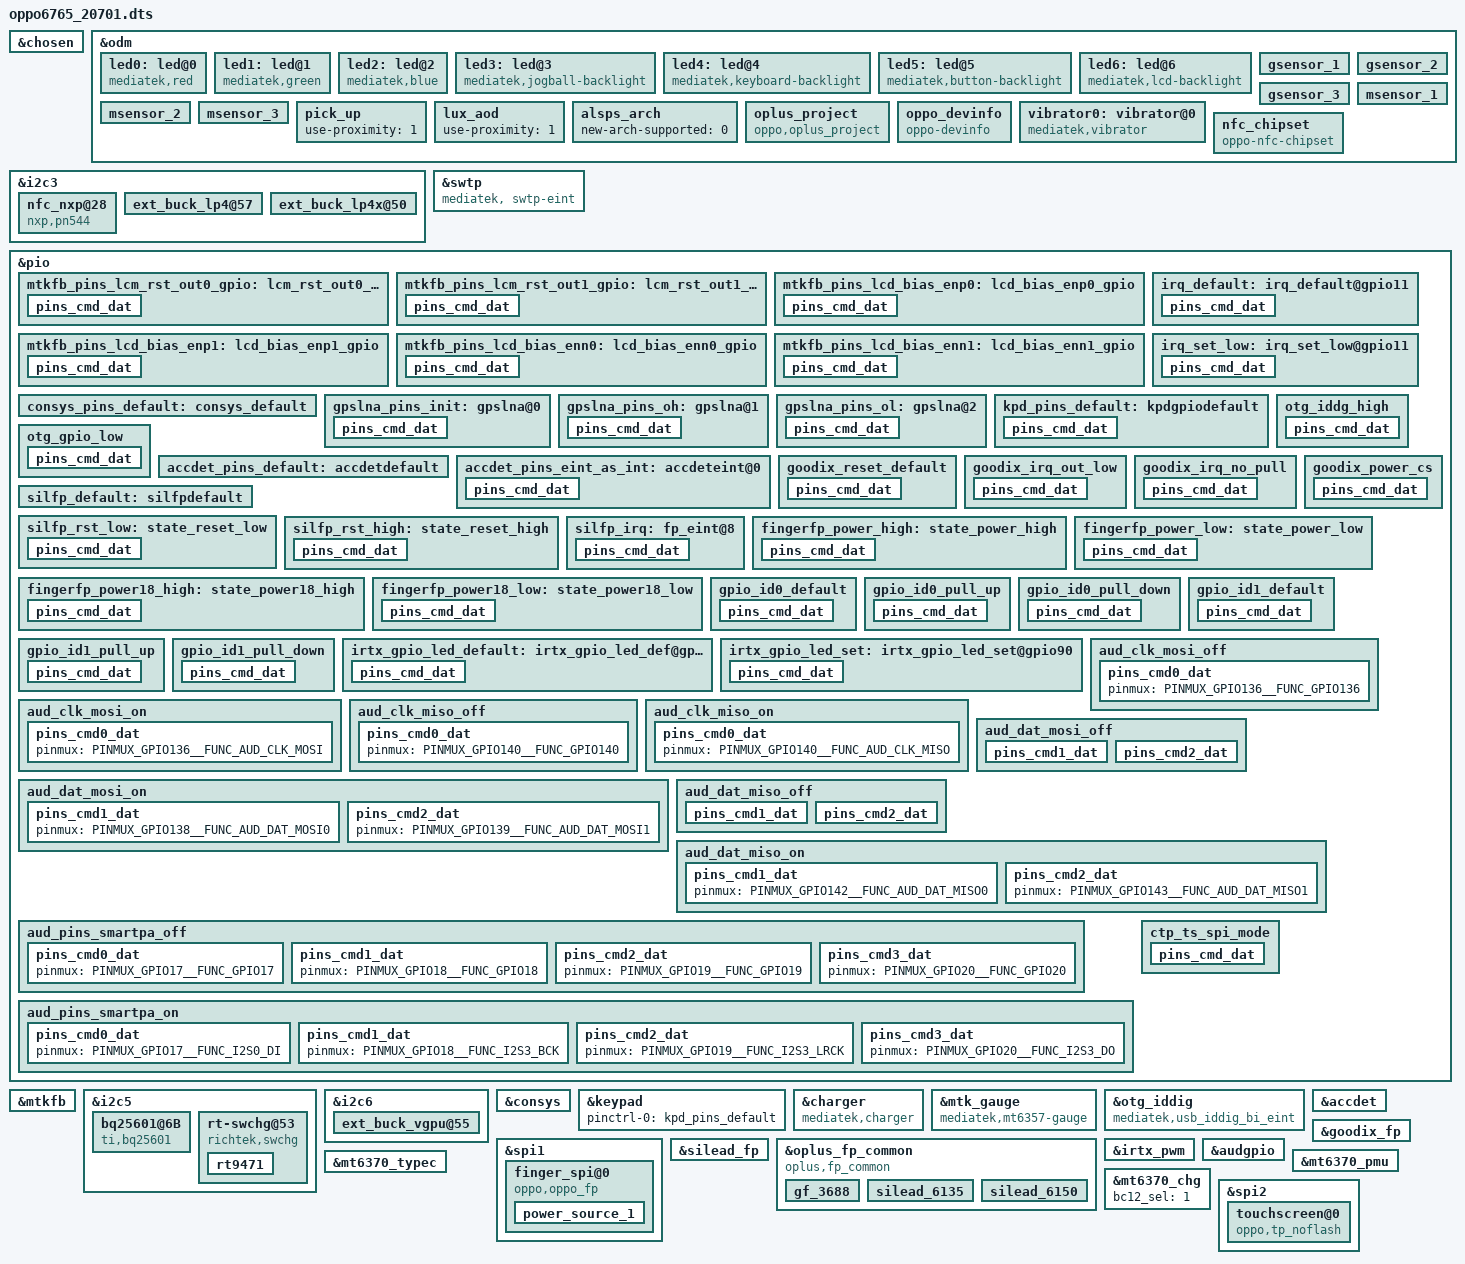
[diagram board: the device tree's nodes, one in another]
// SPDX-License-Identifier: GPL-2.0+
/*
 * Copyright (c) 2019 MediaTek Inc.
 *
 */

#include <dt-bindings/interrupt-controller/arm-gic.h>
#include <dt-bindings/interrupt-controller/irq.h>
#include <dt-bindings/pinctrl/mt6765-pinfunc.h>
#include <dt-bindings/clock/mt6765-clk.h>

/dts-v1/;
/plugin/;

/* chosen */
&chosen {

	/* fpga may has no lk, we need to specify display info here */
	/* fb buffer is reserved using this dts by memory node above */
	atag,videolfb-fb_base_h = <0x0>;
	atag,videolfb-fb_base_l = <0x5e605000>;
	atag,videolfb-islcmfound = <1>;
	/* because no lk, so lcm is not inited */
	atag,videolfb-islcm_inited = <0>;
	atag,videolfb-fps= <6000>;
	atag,videolfb-vramSize= <0x017bb000>;
	atag,videolfb-lcmname= "nt35695B_fhd_dsi_cmd_auo_rt5081_drv";
};

&odm {
	led0:led@0 {
		compatible = "mediatek,red";
		led_mode = <0>;
		data = <1>;
		pwm_config = <0 0 0 0 0>;
	};
	led1:led@1 {
		compatible = "mediatek,green";
		led_mode = <0>;
		data = <1>;
		pwm_config = <0 0 0 0 0>;
	};
	led2:led@2 {
		compatible = "mediatek,blue";
		led_mode = <0>;
		data = <1>;
		pwm_config = <0 0 0 0 0>;
	};
	led3:led@3 {
		compatible = "mediatek,jogball-backlight";
		led_mode = <0>;
		data = <1>;
		pwm_config = <0 0 0 0 0>;
	};
	led4:led@4 {
		compatible = "mediatek,keyboard-backlight";
		led_mode = <0>;
		data = <1>;
		pwm_config = <0 0 0 0 0>;
	};
	led5:led@5 {
		compatible = "mediatek,button-backlight";
		led_mode = <0>;
		data = <1>;
		pwm_config = <0 0 0 0 0>;
	};
	led6:led@6 {
		compatible = "mediatek,lcd-backlight";
		//#ifndef ODM_HQ_EDIT
		led_mode = <4>;
		//#endif
		data = <1>;
		pwm_config = <0 3 0 0 0>;
	};
/*sensor start */
	/*
	enum {
		LIS3DH,
		LSM6DS3,
		BMI160,
		LIS2HH12,
		LSM6DSM,
		BMI2XY,
		LSM6DSO,
		BMA2X2,
		KX022,
		SC7A20,
		MC34X9,
		STK832X,
	};
	*/
	gsensor_1: gsensor_1 {
		status = "okay";
		sensor_name = <7>;//BMA2X2
		i2c_num = <0>;
		i2c_addr = <18>;
		direction = <3>;
		eint_num = <12>;
		step_count_7_en = <1>;
		config_miso = <1>;
		correct_y_bias = <1>;
	};
	gsensor_2: gsensor_2 {
		status = "okay";
		sensor_name = <10>;//MC34X9
		i2c_num = <0>;
		i2c_addr = <0x18>;
		direction = <3>;
		eint_num = <12>;
		step_count_7_en = <1>;
		config_miso = <1>;
		correct_y_bias = <1>;
	};
	gsensor_3: gsensor_3 {
		status = "okay";
		sensor_name = <11>;//STK832X
		i2c_num = <0>;
		i2c_addr = <0x18>;
		direction = <3>;
		eint_num = <12>;
		step_count_7_en = <1>;
		config_miso = <1>;
		correct_y_bias = <1>;
	};
	/*
	enum {
		AKM09911,
		MMC3530,
		MMC5603,
		MXG4300,
		AF6133,
		AF6133E,
	};
	*/
	msensor_1: msensor_1 {
		status = "okay";
		sensor_name = <0>;//AKM09918
		i2c_num = <0>;
		i2c_addr = <0x0c>;
		direction = <3>;
		eint_num = <0>;
	};

	msensor_2: msensor_2 {
		status = "okay";
		sensor_name = <2>;//MMC5603
		i2c_num = <0>;
		i2c_addr = <0x30>;
		direction = <3>;
		eint_num = <0>;
	};
	
	msensor_3: msensor_3 {
		status = "okay";
		sensor_name = <5>;//AF6133E
		i2c_num = <0>;
		i2c_addr = <0x0c>;
		direction = <4>;
		eint_num = <0>;
	};
	pick_up: pick_up {
		status = "okay";
		use-proximity = <1>;
	};
	lux_aod: lux_aod {
		status = "okay";
		use-proximity = <1>;
	};
	alsps_arch: alsps_arch {
		status = "okay";
		new-arch-supported = <0>;
	};
/*sensor end */
/*VNDOR_EDIT oppo project start */
	oplus_project:oplus_project {
		compatible = "oppo,oplus_project";
	};
	oppo_devinfo:oppo_devinfo {
		compatible = "oppo-devinfo";
	};
	vibrator0:vibrator@0 {
		compatible = "mediatek,vibrator";
		vib_timer = <25>;
		vib_limit = <9>;
		vib_vol= <9>;
	};

//#ifdef OPLUS_FEATURE_NFC_CONSOFT
    nfc_chipset:nfc_chipset {
        compatible = "oppo-nfc-chipset";
        chipset-20701-182 = "PN557";
        chipset-20701-183 = "PN557";
    };
//#endif /* OPLUS_FEATURE_NFC_CONSOFT */
};

//#ifdef OPLUS_FEATURE_NFC_BRINGUP
&i2c3 {
       status = "okay";
       nfc_nxp@28 {
               compatible = "nxp,pn544";
               reg = <0x28>;
               nxp,pn544-irq = <&pio 4 0x0>;
               nxp,pn544-ven = <&pio 159 0x0>;
               nxp,pn544-fw-dwnld = <&pio 8 0x0>;
               //pn544-clkreq = <&pio 89 0x0>;
               interrupt-parent = <&pio>;
       };
};
//#endif /* OPLUS_FEATURE_NFC_BRINGUP */

//#ifdef OPLUS_BUG_COMPATIBILITY
&swtp {
		compatible = "mediatek, swtp-eint";
	};
//#endif /*OPLUS_BUG_COMPATIBILITY*/

/* DISPSYS GPIO standardization */
&pio {
	mtkfb_pins_lcm_rst_out0_gpio: lcm_rst_out0_gpio {
		pins_cmd_dat {
			pinmux = <PINMUX_GPIO45__FUNC_GPIO45>;
			slew-rate = <1>;
			output-low;
		};
	};

	mtkfb_pins_lcm_rst_out1_gpio: lcm_rst_out1_gpio {
		pins_cmd_dat {
			pinmux = <PINMUX_GPIO45__FUNC_GPIO45>;
			slew-rate = <1>;
			output-high;
		};
	};

	mtkfb_pins_lcd_bias_enp0: lcd_bias_enp0_gpio {
		pins_cmd_dat {
			pinmux = <PINMUX_GPIO166__FUNC_GPIO166>;
			slew-rate = <1>;
			output-low;
		};
	};

	mtkfb_pins_lcd_bias_enp1: lcd_bias_enp1_gpio {
		pins_cmd_dat {
			pinmux = <PINMUX_GPIO166__FUNC_GPIO166>;
			slew-rate = <1>;
			output-high;
		};
	};

	mtkfb_pins_lcd_bias_enn0: lcd_bias_enn0_gpio {
		pins_cmd_dat {
			pinmux = <PINMUX_GPIO165__FUNC_GPIO165>;
			slew-rate = <1>;
			output-low;
		};
	};

	mtkfb_pins_lcd_bias_enn1: lcd_bias_enn1_gpio {
		pins_cmd_dat {
			pinmux = <PINMUX_GPIO165__FUNC_GPIO165>;
			slew-rate = <1>;
			output-high;
		};
	};
};

&mtkfb {
	pinctrl-names = "lcm_rst_out0_gpio", "lcm_rst_out1_gpio",
		"lcd_bias_enp0_gpio", "lcd_bias_enp1_gpio",
		 "lcd_bias_enn0_gpio", "lcd_bias_enn1_gpio";
	pinctrl-0 = <&mtkfb_pins_lcm_rst_out0_gpio>;
	pinctrl-1 = <&mtkfb_pins_lcm_rst_out1_gpio>;
	pinctrl-2 = <&mtkfb_pins_lcd_bias_enp0>;
	pinctrl-3 = <&mtkfb_pins_lcd_bias_enp1>;
	pinctrl-4 = <&mtkfb_pins_lcd_bias_enn0>;
	pinctrl-5 = <&mtkfb_pins_lcd_bias_enn1>;
	status = "okay";
};

/* DISPSYS GPIO standardization end */

&i2c3 {
	ext_buck_lp4@57 {
		regulator-name ="ext_buck_vdd2";
		regulator-min-microvolt = <300000>;
		regulator-max-microvolt = <1300000>;
		vsel_pin = <0>;
	};

	ext_buck_lp4x@50 {
		regulator-name ="ext_buck_vddq";
		regulator-min-microvolt = <300000>;
		regulator-max-microvolt = <1300000>;
		vsel_pin = <1>;
	};
};

&i2c5 {
	bq25601@6B {
		compatible = "ti,bq25601";
		reg = <0x6b>;
		interrupt-parent = <&pio>;
		interrupts = <11 IRQ_TYPE_EDGE_FALLING 11 0>;
		ti,bq2560x,usb-vlim = <4600>;
		ti,bq2560x,usb-ilim = <500>;
		ti,bq2560x,usb-vreg = <4400>;
		ti,bq2560x,usb-ichg = <500>;
		ti,bq2560x,precharge-current = <256>;
		ti,bq2560x,termination-current = <240>;
		ti,bq2560x,boost-voltage = <4998>;
		ti,bq2560x,boost-current = <1200>;
		ti,bq2560x,enable_term;
		ti,bq2560x,stat-pin-ctrl = <3>;
		ti,bq2560x,vac-ovp-threshold = <6500>;
		ti,bq2560x,charge-detect-enable;

		charger_name = "primary_chg";
		eint_name = "bq2560x";

		pinctrl-names = "irq_default", "irq_set_low";
		pinctrl-0 = <&irq_default>;
		pinctrl-1 = <&irq_set_low>;

		status = "okay";
	};

	rt-swchg@53 {
		compatible = "richtek,swchg";
		reg = <0x53>;
		status = "okay";

		rt,intr_gpio_num = <11>; /* direct defined GPIO num */
		rt,intr_gpio = <&pio 11 0x0>; /* GPIO */
		rt9471 {
			/*
			 * Charger name
			 * Main charger: primary_chg
			 * Slave charger: secondary_chg
			 */
			charger_name = "primary_chg";
			chg_alias_name = "rt9471_chg";
			rm-slave-addr = /bits/ 8 <0x53>;
			rm-name = "rt9471";
			interrupt-names = "wdt", "chg_mivr", "vbus_gd",
					  "bc12_done", "detach", "vac_ov",
					  "otg_fault", "chg_rdy", "chg_done";
			ichg = <1000000>;		/* uA */
			aicr = <500000>;		/* uA */
			mivr = <4400000>;		/* uV */
			cv = <4350000>;			/* uV */
			ieoc = <200000>;		/* uA */
			safe-tmr = <10>;		/* hour */
			wdt = <40>;			/* sec */
			/*
			 * 0: MIVR register
			 * 1: MIVR = VBAT + 200mV
			 * 2: MIVR = VBAT + 250mV
			 * >= 3: MIVR = VBAT + 300mV
			 */
			mivr-track = <0>;
			en-te;
			/* en-jeita; */
			/* ceb-invert; */
			/* dis-i2c-tout; */
			en-qon-rst;
			/* auto-aicr; */
		};
	};
};

&pio {
	irq_default:irq_default@gpio11 {
		pins_cmd_dat {
			pinmux = <PINMUX_GPIO11__FUNC_GPIO11>;
			bias-pull-up;
			input-enable;
		};
	};

	irq_set_low:irq_set_low@gpio11 {
		pins_cmd_dat {
			pinmux = <PINMUX_GPIO11__FUNC_GPIO11>;
			bias-pull-down;
			input-enable;
		};
	};
};

&i2c6 {
	ext_buck_vgpu@55 {
		regulator-name ="ext_buck_vgpu";
		regulator-min-microvolt = <300000>;
		regulator-max-microvolt = <1300000>;
		vsel_pin = <2>;
	};
};

/* CONSYS GPIO standardization */
&pio {
	consys_pins_default: consys_default {
	};
	gpslna_pins_init: gpslna@0 {
		pins_cmd_dat {
			pinmux = <PINMUX_GPIO91__FUNC_GPIO91>;
			slew-rate = <0>;
			bias-disable;
			output-low;
		};
	};
	gpslna_pins_oh: gpslna@1 {
		pins_cmd_dat {
			pinmux = <PINMUX_GPIO91__FUNC_GPIO91>;
			slew-rate = <1>;
			output-high;
		};
	};
	gpslna_pins_ol: gpslna@2 {
		pins_cmd_dat {
			pinmux = <PINMUX_GPIO91__FUNC_GPIO91>;
			slew-rate = <1>;
			output-low;
		};
	};
};
&consys {
	pinctrl-names = "default", "gps_lna_state_init",
		"gps_lna_state_oh", "gps_lna_state_ol";
	pinctrl-0 = <&consys_pins_default>;
	pinctrl-1 = <&gpslna_pins_init>;
	pinctrl-2 = <&gpslna_pins_oh>;
	pinctrl-3 = <&gpslna_pins_ol>;
	status = "okay";
};
/* CONSYS end */

&keypad {
	pinctrl-names = "default";
	pinctrl-0 = <&kpd_pins_default>;
};

&pio {
	kpd_pins_default: kpdgpiodefault {
		pins_cmd_dat {
			pinmux = <PINMUX_GPIO93__FUNC_KPCOL0>;
			bias-pull-up = <MTK_PUPD_SET_R1R0_10>;
			output-low;
			input-schmitt-enable;
		};
	};
};


//#idef OPLUS_CHARGER_BASIC
&charger {
	compatible = "mediatek,charger";
	//pinctrl-names = "default", "charger_gpio_as_output_low","charger_gpio_as_output_high", "ship_sleep", "ship_active", "shortc_active";
	//pinctrl-0 = <&charger_pins_default>;
	//pinctrl-1 = <&charger_pins_eint_output0>;
	//pinctrl-2 = <&charger_pins_eint_output1>;
	//pinctrl-3 = <&ship_sleep_gpio>;
	//pinctrl-4 = <&ship_active_gpio>;
	//pinctrl-5 = <&shortc_active_gpio>;

	//for oplus chg framework:
	qcom,input_current_charger_ma = <2000>;
	qcom,qc_input_current_charger_ma = <2000>;
	qcom,pd_input_current_charger_ma = <2000>;
	qcom,input_current_cdp_ma = <1500>;
	qcom,input_current_usb_ma = <500>;
	qcom,input_current_led_ma = <1200>;
	qcom,input_current_led_ma_forcmcc = <500>;
	qcom,input_current_camera_ma = <1200>;
	qcom,input_current_calling_ma = <1200>;

	qcom,input_current_led_ma_high = <1000>;
	qcom,input_current_led_ma_warm = <1500>;
	qcom,input_current_led_ma_normal = <2000>;

	qcom,led_high_bat_decidegc = <370>;
	qcom,led_warm_bat_decidegc = <350>;

	qcom,iterm_disabled = <0>;
	qcom,iterm_ma = <305>;
	qcom,recharge-mv = <115>;

	qcom,batt_capacity_mah = <5000>; /*typical capacity*/
	//qcom,batt_capacity_mah = <3900>; /*rated capacity*/

	qcom,removed_bat_decidegc = <190>;  /* < -19C */

	qcom,cold_bat_decidegc = <20>;  /* -2C ~ 0C */
	qcom,temp_cold_vfloat_mv = <3980>;
	qcom,temp_cold_fastchg_current_ma = <350>;

	qcom,little_cold_bat_decidegc = <0>;	/* 0C ~ 5C */
	qcom,temp_little_cold_vfloat_mv = <4435>;
	qcom,temp_little_cold_fastchg_current_ma_high = <650>;
	qcom,temp_little_cold_fastchg_current_ma_low = <650>;
	qcom,temp_little_cold_fastchg_current_ma = <650>;
	qcom,temp_little_cold_usbchg_current_ma_high = <650>;
	qcom,temp_little_cold_usbchg_current_ma_low = <650>;
	qcom,temp_little_cold_usbchg_current_ma = <650>;
	qcom,qc_temp_little_cold_fastchg_current_ma_high = <2750>;
	qcom,qc_temp_little_cold_fastchg_current_ma_low = <1650>;

	qcom,cool_bat_decidegc = <50>;	/* 5C ~ 12C */
	qcom,temp_cool_vfloat_mv = <4435>;
	qcom,temp_cool_fastchg_current_ma_high = <1350>;
	qcom,temp_cool_fastchg_current_ma_low = <650>;
	qcom,temp_cool_usbchg_current_ma_high = <650>;
	qcom,temp_cool_usbchg_current_ma_low = <550>;
	qcom,qc_temp_cool_fastchg_current_ma_high = <2750>;
	qcom,qc_temp_cool_fastchg_current_ma_low = <2750>;

	qcom,little_cool_bat_decidegc = <120>;	/* 12C ~ 16C */
	qcom,temp_little_cool_vfloat_mv = <4435>;
	qcom,temp_little_cool_fastchg_current_ma = <2050>;
	qcom,temp_little_cool_usbchg_current_ma = <550>;
	qcom,temp_little_cool_fastchg_current_ma_high = <2050>;
	qcom,temp_little_cool_fastchg_current_ma_low = <2050>;
	qcom,qc_temp_little_cool_fastchg_current_ma = <3400>;

	qcom,normal_bat_decidegc = <160>;	/* 16C ~ 45C */
	qcom,temp_normal_fastchg_current_ma = <2000>;
	qcom,temp_normal_usbchg_current_ma = <550>;
	qcom,temp_normal_vfloat_mv = <4435>;
	qcom,pd_temp_normal_fastchg_current_ma = <3000>;
	qcom,qc_temp_normal_fastchg_current_ma = <3000>;

	qcom,warm_bat_decidegc = <440>;		/* 44C ~ 53C */ /*8pin Bat Vooc project need add 3 degree C*/
	qcom,temp_warm_vfloat_mv = <4130>;
	qcom,temp_warm_fastchg_current_ma = <1200>;
	qcom,temp_warm_usbchg_current_ma = <550>;
	qcom,temp_warm_fastchg_current_ma_led_on = <500>;
	qcom,qc_temp_warm_fastchg_current_ma = <1650>;

	qcom,hot_bat_decidegc = <530>;  /* > 53C */

	qcom,non_standard_vfloat_mv = <3980>;
	qcom,non_standard_fastchg_current_ma = <512>;

	qcom,short_c_bat_cv_mv = <4330>;
	qcom,short_c_bat_vfloat_mv = <3800>;
	qcom,short_c_bat_fastchg_current_ma = <512>;
	qcom,short_c_bat_vfloat_sw_limit = <3750>;

	qcom,cold_vfloat_sw_limit = <3930>;
	qcom,little_cold_vfloat_sw_limit = <4380>;
	qcom,cool_vfloat_sw_limit = <4380>;
	qcom,little_cool_vfloat_sw_limit = <4380>;
	qcom,normal_vfloat_sw_limit = <4380>;
	qcom,warm_vfloat_sw_limit = <4080>;
	qcom,non_standard_vfloat_sw_limit = <3930>;

	qcom,normal_phase1_bat_decidegc = <160>;       /* 16C ~ 22C */
	qcom,temp_normal_phase1_vfloat_mv = <4435>;
	qcom,temp_normal_phase1_fastchg_current_ma = <2200>;

	qcom,normal_phase2_bat_decidegc = <220>;       /* 22C ~ 34C */
	qcom,temp_normal_phase2_vfloat_mv = <4435>;
	qcom,temp_normal_phase2_fastchg_current_ma_high = <2050>;
	qcom,temp_normal_phase2_fastchg_current_ma_low = <2050>;

	qcom,normal_phase3_bat_decidegc = <340>;       /* 34 ~ 36C */
	qcom,temp_normal_phase3_vfloat_mv = <4435>;
	qcom,temp_normal_phase3_fastchg_current_ma_high = <1500>;
	qcom,temp_normal_phase3_fastchg_current_ma_low = <1500>;

	qcom,normal_phase4_bat_decidegc = <360>;       /* 36C ~ 40C */
	qcom,temp_normal_phase4_vfloat_mv = <4435>;
	qcom,temp_normal_phase4_fastchg_current_ma_high = <1250>;
	qcom,temp_normal_phase4_fastchg_current_ma_low = <1250>;

	qcom,normal_phase5_bat_decidegc = <400>;       /* 40C ~ 42C */
	qcom,temp_normal_phase5_vfloat_mv = <4435>;
	qcom,temp_normal_phase5_fastchg_current_ma = <1250>;

	qcom,normal_phase6_bat_decidegc = <420>;       /* 42C ~ 45C */
	qcom,temp_normal_phase6_vfloat_mv = <4435>;
	qcom,temp_normal_phase6_fastchg_current_ma = <1200>;

	qcom,max_chg_time_sec = <60000>;
	qcom,charger_hv_thr = <5800>;
	qcom,charger_recv_thr = <5800>;
	qcom,charger_lv_thr = <3400>;
	qcom,vbatt_full_thr = <4400>;
	qcom,vbatt_hv_thr = <4550>;

	qcom,vfloat_step_mv = <10>;
	qcom,non_standard_vfloat_over_sw_limit = <4000>;
	qcom,cold_vfloat_over_sw_limit = <4000>;
	qcom,little_cold_vfloat_over_sw_limit = <4450>;
	qcom,cool_vfloat_over_sw_limit = <4450>;
	qcom,little_cool_vfloat_over_sw_limit = <4450>;
	qcom,normal_vfloat_over_sw_limit = <4450>;
	qcom,warm_vfloat_over_sw_limit = <4150>;

	qcom,vbatt_power_off = <3300>;
	qcom,vbatt_soc_1 = <3410>;
	qcom,vooc_project = <0>;
	qcom,vbatt_num = <1>;

	qcom,normal_vterm_hw_inc = <150>;
	qcom,non_normal_vterm_hw_inc = <10>;

	qcom,ff1_normal_fastchg_ma = <1088>;
	qcom,ffc2_normal_fastchg_ma = <780>;/*16C~35c*/
	qcom,ffc2_temp_warm_decidegc = <350>;
	qcom,ffc2_warm_fastchg_ma = <840>;/*35C~40c*/
	qcom,ffc2_temp_high_decidegc = <400>;
	qcom,ffc2_temp_low_decidegc = <120>;
	qcom,ff1_exit_step_ma = <488>;
	qcom,ff1_warm_exit_step_ma = <418>;
	qcom,ffc2_exit_step_ma = <180>;
	qcom,ffc2_warm_exit_step_ma = <170>;

	qcom,ffc_normal_vfloat_sw_limit = <4430>;
	qcom,ffc_temp_normal_vfloat_mv = <4500>;
	qcom,ffc_normal_vfloat_over_sw_limit = <4500>;

	qcom,default_iterm_ma = <265>;
	qcom,default_temp_normal_fastchg_current_ma = <2200>;
	qcom,default_normal_vfloat_sw_limit = <4380>;
	qcom,default_temp_normal_vfloat_mv = <4435>;
	qcom,default_normal_vfloat_over_sw_limit = <4450>;

	//for 2nd chip:
	qcom,iterm_ma_2nd = <300>;
	qcom,recharge-mv_2nd = <121>;

	qcom,temp_little_cold_vfloat_mv_2nd = <4391>;	/* 0C ~ 5C */
	qcom,temp_cool_vfloat_mv_2nd = <4391>;	/* 5C ~ 12C */
	qcom,temp_little_cool_vfloat_mv_2nd = <4391>;	/* 12C ~ 16C */
	qcom,temp_normal_vfloat_mv_2nd = <4391>;	/* 16C ~ 45C */

	qcom,little_cold_vfloat_over_sw_limit_2nd = <4395>;
	qcom,cool_vfloat_over_sw_limit_2nd = <4395>;
	qcom,little_cool_vfloat_over_sw_limit_2nd = <4395>;
	qcom,normal_vfloat_over_sw_limit_2nd = <4395>;

	qcom,default_iterm_ma_2nd = <300>;
	qcom,default_temp_normal_vfloat_mv_2nd = <4391>;
	qcom,default_normal_vfloat_over_sw_limit_2nd = <4395>;

	//for control:
	//qcom,suspend_after_full;
	qcom,check_batt_full_by_sw;
	//qcom,external_gauge;
	qcom,chg_ctrl_by_calling;
	qcom,chg_ctrl_by_lcd;
	qcom,chg_ctrl_by_camera;
	qcom,sw_vfloat_over_protect_enable;

	//for PD9V or QC9V
	qcom,vbatt_pdqc_to_5v_thr = <4420>;
	qcom,vbatt_pdqc_to_9v_thr = <4200>;
	qcom,dual_charger_support = <1>;
	qcom,slave_pct = <30>;
	qcom,slave_chg_enable_ma = <1000>;
	qcom,slave_chg_disable_ma = <300>;

	//for step charger
	qcom,step1_time = <600>;		/*10min*/
	qcom,step1_current_ma = <2200>;		/*2200ma*/
	qcom,step2_time = <600>;		/*10min*/
	qcom,step2_current_ma = <2050>;		/*2050ma*/
	qcom,step3_current_ma = <1650>;		/*1650ma*/

	//qcom,ffc_support;

	//GPIO config:
	//qcom,chargerid_switch-gpio = <&pio 97 0x00>;
	//qcom,ship-gpio = <&pio 155 0x00>;
	//qcom,shortc-gpio = <&pio 77 0x00>;

	//io-channels = <&auxadc 3>, <&auxadc 4>;
   //io-channel-names = "usbtemp-ch3", "usbtemp-ch4";

	//qcom,dischg-gpio = <&pio 166 0x00>;
	//pinctrl-names = "dischg_disable", "dischg_enable";
	//pinctrl-0 = <&mtk_pins_usb_burn_en0>;
	//pinctrl-1 = <&mtk_pins_usb_burn_en1>;
	status = "okay";
};

&mtk_gauge {
	compatible = "mediatek,mt6357-gauge";
	charger = <&mt6370_chg>;
	bootmode = <&chosen>;
	io-channels = <&pmic_auxadc 0x03>,
		<&pmic_auxadc 0x00>,
		<&pmic_auxadc 0x0e>,
		<&pmic_auxadc 0x0f>,
		<&pmic_auxadc 0x10>,
		<&auxadc 2>;
	io-channel-names = "pmic_battery_temp",
		"pmic_battery_voltage",
		"pmic_bif_voltage",
		"pmic_ptim_voltage",
		"pmic_ptim_r",
		"auxadc6-batt_id_v";
	nvmem-cells = <&fg_init>, <&fg_soc>;
	nvmem-cell-names = "initialization", "state-of-charge";
	FUELGAGUE_APPLY = <(1)>;
	Enable_Battery_Temp_Compensation = <(0)>;
	Enable_Is_Force_Full = <1>;
	R_FG_VALUE_EXT = <(10)>;
	FG_METER_RESISTANCE_EXT = <(75)>;
	COM_FG_METER_RESISTANCE_EXT = <(75)>;
	CAR_TUNE_VALUE_EXT = <(100)>;
	g_FG_PSEUDO100_T0_EXT = <(98)>;
	g_FG_PSEUDO100_T1_EXT = <(98)>;
	g_FG_PSEUDO100_T2_EXT = <(94)>;
	g_FG_PSEUDO100_T3_EXT = <(87)>;
	g_FG_PSEUDO100_T4_EXT = <(87)>;

	g_PMIC_MIN_VOL_EXT =
	<
	33500 33500 33500 33500
	33500 33500 33500 33500
	33000 33000 33000 33000
	32500 32500 32500 32500
	31500 31000 31000 31000
	31000 31000 31000 31000
	31000 31000 31000 31000
	31000 31000 31000 31000
	31000 31000 31000 31000
	31000 31000 31000 31200
	>;
	g_QMAX_SYS_VOL_EXT =
	<
	33500 33500 33500 33500
	32300 32300 32300 32300
	32800 32800 32800 32800
	33000 33000 33000 33000
	33500 33500 33500 33500
	32500 32500 32500 32500
	32800 32800 32800 32800
	32800 32800 32800 32800
	32800 32800 32800 32800
	32800 32800 32800 32800
	>;
	g_FG_PSEUDO100_EXT =
	<
	98  98  98  98
	98  98  98  98
	94  94  94  94
	87  87  87  87
	87  87  87  87
	100 100 100 100
	100 100 100 100
	100 100 100 100
	100 100 100 100
	100 100 100 100
	>;

	status = "okay";
};

&otg_iddig {
	compatible = "mediatek,usb_iddig_bi_eint";
	interrupt-parent = <&pio>;
	interrupts = <147 IRQ_TYPE_LEVEL_LOW 147 0>;
	pinctrl-names = "otg_iddg_high","otg_gpio_low";
	pinctrl-0 = <&otg_iddg_high>;
	pinctrl-1 = <&otg_gpio_low>;
};

&pio {
	otg_iddg_high:otg_iddg_high {
		pins_cmd_dat {
			pinmux = <PINMUX_GPIO41__FUNC_IDDIG>;
			slew-rate = <0>;
			bias-pull-up;
		};
	};

	otg_gpio_low:otg_gpio_low {
		pins_cmd_dat {
			pinmux = <PINMUX_GPIO41__FUNC_GPIO41>;
			slew-rate = <1>;
			output-low;
		};
	};
};

/* accdet start */
&accdet {
	accdet-mic-vol = <6>;
	headset-mode-setting = <0x500 0x500 1 0x1f0 0x800 0x800 0x20 0x44>;
	accdet-plugout-debounce = <1>;
	accdet-mic-mode = <1>;
	headset-eint-level-pol = <8>;
	headset-three-key-threshold = <0 80 220 400>;
	headset-three-key-threshold-CDD = <0 121 192 600>;
	headset-four-key-threshold = <0 58 121 192 400>;
	pinctrl-names = "default", "state_eint_as_int";
	pinctrl-0 = <&accdet_pins_default>;
	pinctrl-1 = <&accdet_pins_eint_as_int>;
	status = "okay";
};
&pio {
	accdet_pins_default: accdetdefault {
	};
	accdet_pins_eint_as_int: accdeteint@0 {
		pins_cmd_dat {
			pinmux = <PINMUX_GPIO9__FUNC_GPIO9>;
			slew-rate = <0>;
			bias-disable;
		};
	};
};
/* accdet end */

//#ifdef OPLUS_FEATURE_FINGERPRINT
/* FINGERPRINT start */
&spi1 {
	#address-cells = <1>;
	#size-cells = <0>;
	status = "okay";
	finger_spi@0 {
		compatible = "oppo,oppo_fp";
		reg = <0>;
		spi-max-frequency = <8000000>;
		netlink-event = <30>;
		spi-id = <1>;
		spi-irq = <122>;
		spi-reg = <0x11010000>;
		status = "okay";
		goodix,pw_en = <&pio 158 0x00>;
		power_source_1 {
			power-mode = <2>;
			power-name = "goodix,pw_en";
			delay-time = <0>;
		};
	};
};

&pio {
	goodix_reset_default: goodix_reset_default {
		pins_cmd_dat {
			pinmux = <PINMUX_GPIO171__FUNC_GPIO171>;
			slew-rate = <1>;
			output-low;
		};
	};
	goodix_irq_out_low: goodix_irq_out_low {
		pins_cmd_dat {
			pinmux = <PINMUX_GPIO3__FUNC_GPIO3>;
			slew-rate = <1>;
			output-low;
		};
	};
	goodix_irq_no_pull: goodix_irq_no_pull {
		pins_cmd_dat {
			pinmux = <PINMUX_GPIO3__FUNC_GPIO3>;
			slew-rate = <0>;
			bias-disable;
		};
	};
	goodix_power_cs: goodix_power_cs {
		pins_cmd_dat {
			pinmux = <PINMUX_GPIO158__FUNC_GPIO158>;
			slew-rate = <1>;
			bias-disable;
			output-high;
		};
	};    
};

&goodix_fp {
	pinctrl-names = "goodix_reset_default", "goodix_irq_out_low", "goodix_irq_no_pull", "goodix_power_cs";
	pinctrl-0 = <&goodix_reset_default>;
	pinctrl-1 = <&goodix_irq_out_low>;
	pinctrl-2 = <&goodix_irq_no_pull>;
	pinctrl-3 = <&goodix_power_cs>;
	interrupt-parent = <&pio>;
	interrupts = <3 0>;
	goodix,gpio_irq = <&pio 3 0x00>;
	goodix,gpio_reset = <&pio 171 0x00>;
	gf,cs_gpio_disable = <1>;
	goodix,gpio_cs = <&pio 158 0x00>;
	spi-max-frequency = <8000000>;
	status = "okay";
};



/*-------------------the goodix device config end----------------------*/

/*-------------------the silead device config start----------------------*/
&pio {
	silfp_default: silfpdefault {
	};
	silfp_rst_low: state_reset_low {
		pins_cmd_dat {
			pinmux = <PINMUX_GPIO171__FUNC_GPIO171>;
			slew-rate = <1>;
			output-low;
		};
	};
	silfp_rst_high: state_reset_high {
		pins_cmd_dat {
			pinmux = <PINMUX_GPIO171__FUNC_GPIO171>;
			slew-rate = <1>;
			output-high;
		};
	};
	silfp_irq: fp_eint@8 {
		pins_cmd_dat {
			pinmux = <PINMUX_GPIO3__FUNC_GPIO3>;
			slew-rate = <0>;
			bias-disable;
		};
	};
	fingerfp_power_high: state_power_high {
		pins_cmd_dat {
			pinmux = <PINMUX_GPIO158__FUNC_GPIO158>;
			slew-rate = <1>;
			output-high;
		};
	};

	fingerfp_power_low: state_power_low {
		pins_cmd_dat {
			pinmux = <PINMUX_GPIO158__FUNC_GPIO158>;
			slew-rate = <1>;
			output-low;
		};
	};
	fingerfp_power18_high: state_power18_high {
		pins_cmd_dat {
			pinmux = <PINMUX_GPIO158__FUNC_GPIO158>;
			slew-rate = <1>;
			output-high;
		};
	};

	fingerfp_power18_low: state_power18_low {
		pins_cmd_dat {
			pinmux = <PINMUX_GPIO79__FUNC_GPIO79>;
			slew-rate = <1>;
			output-low;
		};
	};
};
&silead_fp {
	sil,silead_irq = <&pio 3 0x00>;
	sil,ldo_disable = <1>;
	pinctrl-names = "default", "rst-low", "rst-high",
	                "irq-init", "power_high","power_low", "power18_high","power18_low";
	pinctrl-0 = <&silfp_default>;
	pinctrl-1 = <&silfp_rst_low>;
	pinctrl-2 = <&silfp_rst_high>;
	pinctrl-3 = <&silfp_irq>;
	pinctrl-4 = <&fingerfp_power_high>;
	pinctrl-5 = <&fingerfp_power_low>;
	pinctrl-6 = <&fingerfp_power18_high>;
	pinctrl-7 = <&fingerfp_power18_low>;
	status = "okay";
};
/*-------------------the silead device config end----------------------*/

/*the finger_id config to project dts.*/
&pio{
        gpio_id0_default: gpio_id0_default {
                pins_cmd_dat {
                        pinmux = <PINMUX_GPIO170__FUNC_GPIO170>;
                        slew-rate = <0>;
                        bias-pull-up = <00>;
                };
        };
        gpio_id0_pull_up: gpio_id0_pull_up {
                pins_cmd_dat {
                        pinmux = <PINMUX_GPIO170__FUNC_GPIO170>;
                        slew-rate = <0>;
                        bias-pull-up = <00>;
                };
        };
        gpio_id0_pull_down: gpio_id0_pull_down {
                pins_cmd_dat {
                        pinmux = <PINMUX_GPIO170__FUNC_GPIO170>;
                        slew-rate = <0>;
                        bias-pull-down = <00>;
                };
        };
};

&pio{
        gpio_id1_default: gpio_id1_default {
                pins_cmd_dat {
                        pinmux = <PINMUX_GPIO173__FUNC_GPIO173>;
                        slew-rate = <0>;
                        bias-pull-up = <00>;
                };
        };
        gpio_id1_pull_up: gpio_id1_pull_up {
                pins_cmd_dat {
                        pinmux = <PINMUX_GPIO173__FUNC_GPIO173>;
                        slew-rate = <0>;
                        bias-pull-up = <00>;
                };
        };
        gpio_id1_pull_down: gpio_id1_pull_down {
                pins_cmd_dat {
                        pinmux = <PINMUX_GPIO173__FUNC_GPIO173>;
                        slew-rate = <0>;
                        bias-pull-down = <00>;
                };
        };
};

&oplus_fp_common {
        compatible = "oplus,fp_common"; //Manufacture, and Model
        oplus,fp_gpio_num = <2>;
        oplus,fp_gpio_0 = <&pio 170 0x00>;
        oplus,fp_gpio_1 = <&pio 173 0x00>;
        pinctrl-names = "gpio_id0_default", "gpio_id0_pull_up", "gpio_id0_pull_down", "gpio_id1_default", "gpio_id1_pull_up", "gpio_id1_pull_down";
        pinctrl-0 = <&gpio_id0_default>;
        pinctrl-1 = <&gpio_id0_pull_up>;
        pinctrl-2 = <&gpio_id0_pull_down>;
        pinctrl-3 = <&gpio_id1_default>;
        pinctrl-4 = <&gpio_id1_pull_up>;
        pinctrl-5 = <&gpio_id1_pull_down>;
        gf_3688 {
                oplus,fp-id = <1 0>; /* fp id mapping table */
                vendor-chip = <16>; /* please refer to the struct fp_vendor_t in oppo_fp_commmon.n */
                eng-menu = "-1,-1"; /* represents SNR, inclination test item in engineer menu, and 0/1 means off/on */
                chip-name = "G_3688";  /* /proc/fp_id, will be displayed in engineer menu  */
        };
        silead_6135 {
                oplus,fp-id = <0 1>; /* fp id mapping table */
                vendor-chip = <21>; /* please refer to the struct fp_vendor_t in oppo_fp_commmon.n */
                eng-menu = "-1,-1"; /* represents SNR, inclination test item in engineer menu, and 0/1 means off/on */
                chip-name = "G_6135";  /* /proc/fp_id, will be displayed in engineer menu  */
        };
        silead_6150 {
                oplus,fp-id = <0 0>; /* fp id mapping table */
                vendor-chip = <21>; /* please refer to the struct fp_vendor_t in oppo_fp_commmon.n */
                eng-menu = "-1,-1"; /* represents SNR, inclination test item in engineer menu, and 0/1 means off/on */
                chip-name = "S_gsl6150";  /* /proc/fp_id, will be displayed in engineer menu  */
        };
};
/* FINGERPRINT end */
//#endif /*OPLUS_FEATURE_FINGERPRINT*/

/* IRTX GPIO end */
&irtx_pwm {
	pinctrl-names = "irtx_gpio_led_default", "irtx_gpio_led_set";
	pinctrl-0 = <&irtx_gpio_led_default>;
	pinctrl-1 = <&irtx_gpio_led_set>;
	status = "okay";
};
&pio {
	irtx_gpio_led_default:irtx_gpio_led_def@gpio90 {
		pins_cmd_dat {
			pinmux = <PINMUX_GPIO90__FUNC_GPIO90>;
			slew-rate = <1>;
			bias-disable;
			output-low;
			input-schmitt-enable = <0>;
		};
	};

	irtx_gpio_led_set:irtx_gpio_led_set@gpio90 {
		pins_cmd_dat {
			pinmux = <PINMUX_GPIO90__FUNC_PWM0>;
			slew-rate = <1>;
			output-high;
		};
	};
};
/* IRTX GPIO Settings -End */

/* AUDIO GPIO standardization */
&audgpio {
	pinctrl-names = "aud_clk_mosi_off",
			"aud_clk_mosi_on",
			"aud_clk_miso_off",
			"aud_clk_miso_on",
			"aud_dat_mosi_off",
			"aud_dat_mosi_on",
			"aud_dat_miso_off",
			"aud_dat_miso_on",
			"aud_smartpa_off",
			"aud_smartpa_on";
	pinctrl-0 = <&aud_clk_mosi_off>;
	pinctrl-1 = <&aud_clk_mosi_on>;
	pinctrl-2 = <&aud_clk_miso_off>;
	pinctrl-3 = <&aud_clk_miso_on>;
	pinctrl-4 = <&aud_dat_mosi_off>;
	pinctrl-5 = <&aud_dat_mosi_on>;
	pinctrl-6 = <&aud_dat_miso_off>;
	pinctrl-7 = <&aud_dat_miso_on>;
	pinctrl-8 = <&aud_pins_smartpa_off>;
	pinctrl-9 = <&aud_pins_smartpa_on>;
	status = "okay";
};

&pio {
	aud_clk_mosi_off: aud_clk_mosi_off {
		pins_cmd0_dat {
			pinmux = <PINMUX_GPIO136__FUNC_GPIO136>;
		};
	};

	aud_clk_mosi_on: aud_clk_mosi_on {
		pins_cmd0_dat {
			pinmux = <PINMUX_GPIO136__FUNC_AUD_CLK_MOSI>;
		};
	};

	aud_clk_miso_off: aud_clk_miso_off {
		pins_cmd0_dat {
			pinmux = <PINMUX_GPIO140__FUNC_GPIO140>;
		};
	};

	aud_clk_miso_on: aud_clk_miso_on {
		pins_cmd0_dat {
			pinmux = <PINMUX_GPIO140__FUNC_AUD_CLK_MISO>;
		};
	};

	aud_dat_mosi_off: aud_dat_mosi_off {
		pins_cmd1_dat {
			pinmux = <PINMUX_GPIO138__FUNC_GPIO138>;
			input-enable;
			slew-rate = <0>;
			bias-disable;
		};
		pins_cmd2_dat {
			pinmux = <PINMUX_GPIO139__FUNC_GPIO139>;
			input-enable;
			slew-rate = <0>;
			bias-disable;
		};
	};

	aud_dat_mosi_on: aud_dat_mosi_on {
		pins_cmd1_dat {
			pinmux = <PINMUX_GPIO138__FUNC_AUD_DAT_MOSI0>;
		};
		pins_cmd2_dat {
			pinmux = <PINMUX_GPIO139__FUNC_AUD_DAT_MOSI1>;
		};
	};

	aud_dat_miso_off: aud_dat_miso_off {
		pins_cmd1_dat {
			pinmux = <PINMUX_GPIO142__FUNC_GPIO142>;
			input-enable;
			slew-rate = <0>;
			bias-disable;
		};
		pins_cmd2_dat {
			pinmux = <PINMUX_GPIO143__FUNC_GPIO143>;
			input-enable;
			slew-rate = <0>;
			bias-disable;
		};
	};

	aud_dat_miso_on: aud_dat_miso_on {
		pins_cmd1_dat {
			pinmux = <PINMUX_GPIO142__FUNC_AUD_DAT_MISO0>;
		};
		pins_cmd2_dat {
			pinmux = <PINMUX_GPIO143__FUNC_AUD_DAT_MISO1>;
		};
	};

	aud_pins_smartpa_off: aud_pins_smartpa_off {
		pins_cmd0_dat {
			pinmux = <PINMUX_GPIO17__FUNC_GPIO17>;
		};
		pins_cmd1_dat {
			pinmux = <PINMUX_GPIO18__FUNC_GPIO18>;
		};
		pins_cmd2_dat {
			pinmux = <PINMUX_GPIO19__FUNC_GPIO19>;
		};
		pins_cmd3_dat {
			pinmux = <PINMUX_GPIO20__FUNC_GPIO20>;
		};
	};

	aud_pins_smartpa_on: aud_pins_smartpa_on {
		pins_cmd0_dat {
			pinmux = <PINMUX_GPIO17__FUNC_I2S0_DI>;
		};
		pins_cmd1_dat {
			pinmux = <PINMUX_GPIO18__FUNC_I2S3_BCK>;
		};
		pins_cmd2_dat {
			pinmux = <PINMUX_GPIO19__FUNC_I2S3_LRCK>;
		};
		pins_cmd3_dat {
			pinmux = <PINMUX_GPIO20__FUNC_I2S3_DO>;
		};
	};
};
/* AUDIO end */

&mt6370_pmu {
	mt6370,intr_gpio_num = <11>; /* direct defined GPIO num */
	mt6370,intr_gpio = <&pio 11 0x0>;
};

&mt6370_typec {
	mt6370pd,intr_gpio_num = <41>; /* direct defined GPIO num */
	mt6370pd,intr_gpio = <&pio 41 0x0>;
};

&mt6370_chg {
	bc12_sel = <1>;
};

/* Touch start */

&spi2 {
	touchscreen@0 {
		compatible = "oppo,tp_noflash";
		reg = <0>;
		chip-name = "OPPO_TP_NOFLASH";
		status = "ok";

		spi-max-frequency = <15000000>;    //4800000,9600000,15000000,19200000
		reset-gpio = <&pio 178 0>;
		interrupt-parent = <&pio>;
		interrupts = <0 IRQ_TYPE_EDGE_FALLING 0 0>;
		irq-gpio = <&pio 0 0x2002>;

		platform_support_project = <20701>;
		platform_support_project_dir = <20701>;
		platform_support_project_commandline = "default_commandline";

		touchpanel,max-num-support = <10>;
		touchpanel,tx-rx-num = <18 32>;
		touchpanel,panel-coords = <720 1600>;
		touchpanel,display-coords = <720 1600>;
		touchpanel,touchmajor-limit = <0 54>;

		pinctrl-names = "default";
		pinctrl-0 = <&ctp_ts_spi_mode>;


		incell_screen;
		fw_edge_limit_support;
		black_gesture_support;
		charger_pump_support;
		headset_pump_support;
		esd_handle_support;
		//spurious_fingerprint_support;
		black_gesture_test_support;
		noflash_support;
		smart_gesture_support;
		pressure_report_support;
		fw_update_app_support;
		game_switch_support;
		drlimit_remove_support;
		lcd_trigger_load_tp_fw_support;
		suspend_gesture_cfg;
		irq_need_dev_resume_ok;
		fw_update_in_probe_with_headfile;

		touchpanel,button-type = <4>;
	};
};
&pio {
	ctp_ts_spi_mode: ctp_ts_spi_mode {
		pins_cmd_dat {
			pinmux = <PINMUX_GPIO17__FUNC_SPI2_MO>,
				<PINMUX_GPIO18__FUNC_SPI2_CLK>,
				<PINMUX_GPIO19__FUNC_SPI2_MI>,
				<PINMUX_GPIO20__FUNC_SPI2_CSB>;
			drive-strength = <4>;
		};
	};
};
/* touch end */
#include "oppo6765_20701/cust.dtsi"
#include "mediatek/cust_mt6765_camera_20701.dtsi"
/*#include "mediatek/cust_mt6765_touch_1080x1920.dtsi"*/
/*End of this file, DO NOT ADD ANYTHING HERE*/
